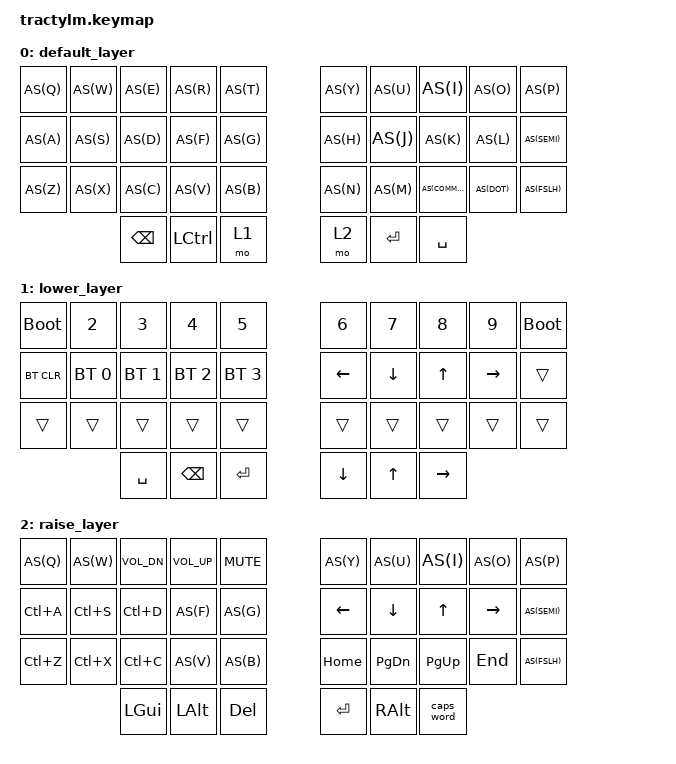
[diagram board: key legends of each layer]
/*
 * Copyright (c) 2020 The ZMK Contributors
 *
 * SPDX-License-Identifier: MIT
 */
/**/

#include <behaviors.dtsi>
#include <dt-bindings/zmk/keys.h>
#include <dt-bindings/zmk/bt.h>



#define DEFAULT 0
#define RAISE 1
#define LOWER 2

#define AS(keycode) &as LS(keycode) keycode

/ {
        behaviors {
            as: auto_shift {
                compatible = "zmk,behavior-hold-tap";
                label = "AUTO_SHIFT";
                #binding-cells = <2>;
                tapping_term_ms = <200>;
                quick_tap_ms = <10>;
                flavor = "tap-preferred";
                bindings = <&kp>, <&kp>;
            };
        };
        
        
    keymap {
        compatible = "zmk,keymap";

        default_layer {
// ------------------------------------------------------------------------------------------------------------
// |  Q  |  W  |  E   |  R   |  T    |                   |  Y   |  U     |  I    |  O   |   P   |
// |  A  |  S  |  D   |  F   |  G    |                   |  H   |  J     |  K    |  L   |   ;   |
// |  Z  |  X  |  C   |  V   |  B    |                   |  N   |  M     |  ,    |  .   |   /   |
//             | BKSPC| CTRL |  ALT  |                   | SHIFT|  GUI   | ENTR  |

            bindings = <
AS(Q)  AS(W)    AS(E)    AS(R)     AS(T)                       AS(Y)  AS(U)     AS(I)     AS(O)    AS(P)   
AS(A)  AS(S)    AS(D)    AS(F)     AS(G)                       AS(H)  AS(J)     AS(K)     AS(L)    AS(SEMI)
AS(Z)  AS(X)    AS(C)    AS(V)     AS(B)                       AS(N)  AS(M)     AS(COMMA) AS(DOT)  AS(FSLH)
                 &kp BSPC &kp LCTRL &mo 1                      &mo 2 &kp ENTER &kp SPACE 
            >;
        };

        lower_layer {
// TODO: Some binds are waiting for shifted keycode support.
// ------------------------------------------------------------------------------------------------------------
// |   1 |   2 |   3  |   4  |   5  |                   |   6  |   7   |   8   |   9  |    0  |
// |  !  |  @  |  #   |  $   |  %   |                   |  ^   |  &    |  *    |  (   |   )   |
// |  =  |  -  |  +   |  {   |  }   |        			|  [   |  ]    |  ;    |  :   |   \   |
//             | GUI | ALT  |   SPACE|                  |  ENTR  | ALT   | GUI  |

           bindings = <
   &bootloader			&kp N2			&kp N3			&kp N4			&kp N5         			&kp N6   	&kp N7		&kp N8		&kp N9		&bootloader
   &bt BT_CLR 		&bt BT_SEL 0	&bt BT_SEL 1	&bt BT_SEL 2	&bt BT_SEL 3 			&kp LEFT	&kp DOWN	&kp UP		&kp RIGHT	&trans
   &trans			&trans			&trans			&trans			&trans         			&trans		&trans		&trans		&trans		&trans
									&kp SPACE	 	&kp BSPC		&kp ENTER				&kp DOWN	&kp UP  	&kp RIGHT   	                
            >;
       
        };

        raise_layer {
// ------------------------------------------------------------------------------------------------------------
// |     | INS  | PSCR | GUI   |       |      |                | PGUP |      |   ^   |      |       |       |
// |     | ALT  | CTRL | SHIFT |       | CAPS |                | PGDN |   <- |   v   |  ->  |  DEL  | BKSPC |
// |     | UNDO | CUT  | COPY  | PASTE |      |      |  |      |      |      |       |      |       |       |
//              |      |       |       |      |      |  |      |      |      |       |      |
           bindings = <
AS(Q)      AS(W)     &kp K_VOL_DN &kp K_VOL_UP  &kp K_MUTE                   AS(Y)    AS(U)     AS(I)     AS(O)      AS(P)    
&kp LC(A)  &kp LC(S) &kp LC(D) AS(F)  AS(G)                   &kp LEFT &kp DOWN  &kp UP    &kp RIGHT AS(SEMI) 
&kp LC(Z)  &kp LC(X) &kp LC(C) AS(V)  AS(B)                   &kp HOME &kp PG_DN &kp PG_UP &kp END    AS(FSLH)
                     &kp LGUI  &kp LALT &kp DELETE          &kp ENTER  &kp RALT &caps_word                
            >;
  
        };
    };
};
